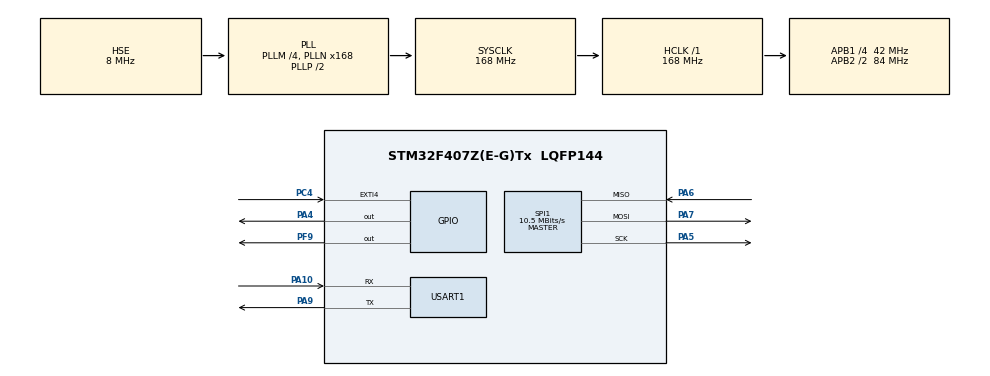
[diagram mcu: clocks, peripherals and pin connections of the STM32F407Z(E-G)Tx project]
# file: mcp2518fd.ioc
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FREERTOS.Tasks01=defaultTask,0,128,StartDefaultTask,Default,NULL,Dynamic,NULL,NULL
Mcu.Family=STM32F4
Mcu.Name=STM32F407Z(E-G)Tx
Mcu.Package=LQFP144
NVIC.EXTI4_IRQn=true\:5\:0\:false\:false\:true\:true\:true\:true\:true
NVIC.PriorityGroup=NVIC_PRIORITYGROUP_4
NVIC.TIM1_UP_TIM10_IRQn=true\:15\:0\:false\:false\:true\:false\:false\:true\:true
NVIC.TimeBase=TIM1_UP_TIM10_IRQn
NVIC.TimeBaseIP=TIM1
PA10.Mode=Asynchronous
PA10.Signal=USART1_RX
PA13.Mode=Trace_Asynchronous_SW
PA13.Signal=SYS_JTMS-SWDIO
PA14.Mode=Trace_Asynchronous_SW
PA14.Signal=SYS_JTCK-SWCLK
PA4.GPIO_Speed=GPIO_SPEED_FREQ_VERY_HIGH
PA4.PinState=GPIO_PIN_SET
PA4.Signal=GPIO_Output
PA5.Mode=Full_Duplex_Master
PA5.Signal=SPI1_SCK
PA6.Mode=Full_Duplex_Master
PA6.Signal=SPI1_MISO
PA7.Mode=Full_Duplex_Master
PA7.Signal=SPI1_MOSI
PA9.Mode=Asynchronous
PA9.Signal=USART1_TX
PB3.Mode=Trace_Asynchronous_SW
PB3.Signal=SYS_JTDO-SWO
PC4.GPIO_ModeDefaultEXTI=GPIO_MODE_IT_FALLING
PC4.Signal=GPXTI4
PF9.Signal=GPIO_Output
PH0-OSC_IN.Mode=HSE-External-Oscillator
PH0-OSC_IN.Signal=RCC_OSC_IN
PH1-OSC_OUT.Mode=HSE-External-Oscillator
PH1-OSC_OUT.Signal=RCC_OSC_OUT
ProjectManager.HeapSize=0x200
ProjectManager.StackSize=0x400
ProjectManager.TargetToolchain=MDK-ARM V5.32
RCC.48MHZClocksFreq_Value=84000000
RCC.AHBFreq_Value=168000000
RCC.APB1CLKDivider=RCC_HCLK_DIV4
RCC.APB1Freq_Value=42000000
RCC.APB1TimFreq_Value=84000000
RCC.APB2CLKDivider=RCC_HCLK_DIV2
RCC.APB2Freq_Value=84000000
RCC.APB2TimFreq_Value=168000000
RCC.CortexFreq_Value=168000000
RCC.HCLKFreq_Value=168000000
RCC.HSE_VALUE=8000000
RCC.HSI_VALUE=16000000
RCC.LSE_VALUE=32768
RCC.PLLM=4
RCC.PLLN=168
RCC.PLLSourceVirtual=RCC_PLLSOURCE_HSE
RCC.SYSCLKFreq_VALUE=168000000
RCC.SYSCLKSource=RCC_SYSCLKSOURCE_PLLCLK
RCC.VCOOutputFreq_Value=336000000
SPI1.BaudRatePrescaler=SPI_BAUDRATEPRESCALER_8
SPI1.CLKPhase=SPI_PHASE_2EDGE
SPI1.CLKPolarity=SPI_POLARITY_HIGH
SPI1.CalculateBaudRate=10.5 MBits/s
SPI1.Direction=SPI_DIRECTION_2LINES
SPI1.Mode=SPI_MODE_MASTER
SPI1.VirtualType=VM_MASTER
USART1.VirtualMode=VM_ASYNC
VP_FREERTOS_VS_CMSIS_V1.Mode=CMSIS_V1
VP_SYS_VS_tim1.Mode=TIM1
board=custom

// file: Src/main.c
/* USER CODE BEGIN Header */
/**
  ******************************************************************************
  * @file           : main.c
  * @brief          : Main program body
  ******************************************************************************
  * @attention
  *
  * Copyright (c) 2023 STMicroelectronics.
  * All rights reserved.
  *
  * This software is licensed under terms that can be found in the LICENSE file
  * in the root directory of this software component.
  * If no LICENSE file comes with this software, it is provided AS-IS.
  *
  ******************************************************************************
  */
/* USER CODE END Header */
#include "main.h"
#include "cmsis_os.h"
#include "spi.h"
#include "usart.h"
#include "gpio.h"

/* USER CODE BEGIN Includes */
//#include "drv_spi.h"
/* USER CODE END Includes */

void SystemClock_Config(void);
void MX_FREERTOS_Init(void);

int main(void)
{

  /* MCU Configuration--------------------------------------------------------*/

  /* Reset of all peripherals, Initializes the Flash interface and the Systick. */
  HAL_Init();

  /* Configure the system clock */
  SystemClock_Config();

  /* Initialize all configured peripherals */
  MX_GPIO_Init();
  MX_SPI1_Init();
  MX_USART1_UART_Init();
  /* USER CODE BEGIN 2 */
//  DRV_SPI_Initialize();
  /* USER CODE END 2 */

  /* Call init function for freertos objects (in freertos.c) */
  MX_FREERTOS_Init();

  /* Start scheduler */
  osKernelStart();
  /* We should never get here as control is now taken by the scheduler */
  /* Infinite loop */
  while (1)
  {

  }
}

void SystemClock_Config(void)
{
  RCC_OscInitTypeDef RCC_OscInitStruct = {0};
  RCC_ClkInitTypeDef RCC_ClkInitStruct = {0};

  /** Configure the main internal regulator output voltage
  */
  __HAL_RCC_PWR_CLK_ENABLE();
  __HAL_PWR_VOLTAGESCALING_CONFIG(PWR_REGULATOR_VOLTAGE_SCALE1);

  /** Initializes the RCC Oscillators according to the specified parameters
  * in the RCC_OscInitTypeDef structure.
  */
  RCC_OscInitStruct.OscillatorType = RCC_OSCILLATORTYPE_HSE;
  RCC_OscInitStruct.HSEState = RCC_HSE_ON;
  RCC_OscInitStruct.PLL.PLLState = RCC_PLL_ON;
  RCC_OscInitStruct.PLL.PLLSource = RCC_PLLSOURCE_HSE;
  RCC_OscInitStruct.PLL.PLLM = 4;
  RCC_OscInitStruct.PLL.PLLN = 168;
  RCC_OscInitStruct.PLL.PLLP = RCC_PLLP_DIV2;
  RCC_OscInitStruct.PLL.PLLQ = 4;
  if (HAL_RCC_OscConfig(&RCC_OscInitStruct) != HAL_OK)
  {
    Error_Handler();
  }

  /** Initializes the CPU, AHB and APB buses clocks
  */
  RCC_ClkInitStruct.ClockType = RCC_CLOCKTYPE_HCLK|RCC_CLOCKTYPE_SYSCLK
                              |RCC_CLOCKTYPE_PCLK1|RCC_CLOCKTYPE_PCLK2;
  RCC_ClkInitStruct.SYSCLKSource = RCC_SYSCLKSOURCE_PLLCLK;
  RCC_ClkInitStruct.AHBCLKDivider = RCC_SYSCLK_DIV1;
  RCC_ClkInitStruct.APB1CLKDivider = RCC_HCLK_DIV4;
  RCC_ClkInitStruct.APB2CLKDivider = RCC_HCLK_DIV2;

  if (HAL_RCC_ClockConfig(&RCC_ClkInitStruct, FLASH_LATENCY_5) != HAL_OK)
  {
    Error_Handler();
  }
}

void HAL_TIM_PeriodElapsedCallback(TIM_HandleTypeDef *htim)
{
  if (htim->Instance == TIM1) {
    HAL_IncTick();
  }
}

void Error_Handler(void)
{
  __disable_irq();
  while (1)
  {
  }
}

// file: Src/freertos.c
/* USER CODE BEGIN Header */
/**
  ******************************************************************************
  * File Name          : freertos.c
  * Description        : Code for freertos applications
  ******************************************************************************
  * @attention
  *
  * Copyright (c) 2023 STMicroelectronics.
  * All rights reserved.
  *
  * This software is licensed under terms that can be found in the LICENSE file
  * in the root directory of this software component.
  * If no LICENSE file comes with this software, it is provided AS-IS.
  *
  ******************************************************************************
  */
/* USER CODE END Header */

#include "FreeRTOS.h"
#include "task.h"
#include "main.h"
#include "cmsis_os.h"

osThreadId defaultTaskHandle;

void StartDefaultTask(void const * argument);

void MX_FREERTOS_Init(void); /* (MISRA C 2004 rule 8.1) */

/* GetIdleTaskMemory prototype (linked to static allocation support) */
void vApplicationGetIdleTaskMemory( StaticTask_t **ppxIdleTaskTCBBuffer, StackType_t **ppxIdleTaskStackBuffer, uint32_t *pulIdleTaskStackSize );

/* USER CODE BEGIN GET_IDLE_TASK_MEMORY */
static StaticTask_t xIdleTaskTCBBuffer;
static StackType_t xIdleStack[configMINIMAL_STACK_SIZE];

void vApplicationGetIdleTaskMemory( StaticTask_t **ppxIdleTaskTCBBuffer, StackType_t **ppxIdleTaskStackBuffer, uint32_t *pulIdleTaskStackSize )
{
  *ppxIdleTaskTCBBuffer = &xIdleTaskTCBBuffer;
  *ppxIdleTaskStackBuffer = &xIdleStack[0];
  *pulIdleTaskStackSize = configMINIMAL_STACK_SIZE;
  /* place for user code */
}
/* USER CODE END GET_IDLE_TASK_MEMORY */

void MX_FREERTOS_Init(void) {

  /* Create the thread(s) */
  /* definition and creation of defaultTask */
  osThreadDef(defaultTask, StartDefaultTask, osPriorityNormal, 0, 128);
  defaultTaskHandle = osThreadCreate(osThread(defaultTask), NULL);

}

void StartDefaultTask(void const * argument)
{
  /* USER CODE BEGIN StartDefaultTask */
  /* Infinite loop */
  for(;;)
  {
    osDelay(500);
    HAL_GPIO_TogglePin(GPIOF, GPIO_PIN_9);
  }
  /* USER CODE END StartDefaultTask */
}
